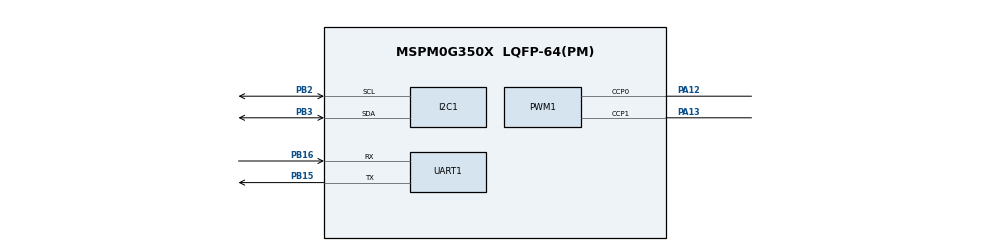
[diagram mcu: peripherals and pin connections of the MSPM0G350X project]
/**
 * @cliArgs --device "MSPM0G350X" --part "Default" --package "LQFP-64(PM)" --product "mspm0_sdk@2.10.00.04"
 * @versions {"tool":"1.27.0+4565"}
 */

/**
 * Import the modules used in this configuration.
 */
const GPIO   = scripting.addModule("/ti/driverlib/GPIO", {}, false);
const GPIO1  = GPIO.addInstance();
const GPIO2  = GPIO.addInstance();
const GPIO3  = GPIO.addInstance();
const GPIO4  = GPIO.addInstance();
const ADC12  = scripting.addModule("/ti/driverlib/ADC12", {}, false);
const ADC121 = ADC12.addInstance();
const I2C    = scripting.addModule("/ti/driverlib/I2C", {}, false);
const I2C1   = I2C.addInstance();
const PWM    = scripting.addModule("/ti/driverlib/PWM", {}, false);
const PWM1   = PWM.addInstance();
const SYSCTL = scripting.addModule("/ti/driverlib/SYSCTL");
const TIMER  = scripting.addModule("/ti/driverlib/TIMER", {}, false);
const TIMER1 = TIMER.addInstance();
const UART   = scripting.addModule("/ti/driverlib/UART", {}, false);
const UART1  = UART.addInstance();
const WWDT   = scripting.addModule("/ti/driverlib/WWDT", {}, false);
const WWDT1  = WWDT.addInstance();

/**
 * Write custom configuration values to the imported modules.
 */
GPIO1.$name                          = "MOTOR";
GPIO1.associatedPins.create(5);
GPIO1.associatedPins[0].assignedPort = "PORTA";
GPIO1.associatedPins[0].$name        = "A_IN1";
GPIO1.associatedPins[0].assignedPin  = "24";
GPIO1.associatedPins[1].assignedPort = "PORTA";
GPIO1.associatedPins[1].$name        = "A_IN2";
GPIO1.associatedPins[1].assignedPin  = "25";
GPIO1.associatedPins[2].assignedPort = "PORTB";
GPIO1.associatedPins[2].assignedPin  = "9";
GPIO1.associatedPins[2].$name        = "B_IN1";
GPIO1.associatedPins[3].assignedPort = "PORTB";
GPIO1.associatedPins[3].assignedPin  = "8";
GPIO1.associatedPins[3].$name        = "B_IN2";
GPIO1.associatedPins[4].assignedPort = "PORTB";
GPIO1.associatedPins[4].assignedPin  = "22";
GPIO1.associatedPins[4].initialValue = "SET";
GPIO1.associatedPins[4].$name        = "STBY";

const Board = scripting.addModule("/ti/driverlib/Board", {}, false);

GPIO2.$name                              = "KEY";
GPIO2.associatedPins.create(3);
GPIO2.associatedPins[0].$name            = "SW1";
GPIO2.associatedPins[0].direction        = "INPUT";
GPIO2.associatedPins[0].internalResistor = "PULL_UP";
GPIO2.associatedPins[0].assignedPort     = "PORTB";
GPIO2.associatedPins[0].assignedPin      = "23";
GPIO2.associatedPins[1].$name            = "SW2";
GPIO2.associatedPins[1].direction        = "INPUT";
GPIO2.associatedPins[1].internalResistor = "PULL_UP";
GPIO2.associatedPins[1].assignedPort     = "PORTA";
GPIO2.associatedPins[1].assignedPin      = "8";
GPIO2.associatedPins[2].$name            = "SW3";
GPIO2.associatedPins[2].direction        = "INPUT";
GPIO2.associatedPins[2].internalResistor = "PULL_UP";
GPIO2.associatedPins[2].assignedPort     = "PORTB";
GPIO2.associatedPins[2].assignedPin      = "6";

GPIO3.$name                              = "ENCODER";
GPIO3.associatedPins.create(4);
GPIO3.associatedPins[0].$name            = "ENC_LA";
GPIO3.associatedPins[0].direction        = "INPUT";
GPIO3.associatedPins[0].assignedPort     = "PORTA";
GPIO3.associatedPins[0].assignedPin      = "14";
GPIO3.associatedPins[0].internalResistor = "PULL_UP";
GPIO3.associatedPins[1].direction        = "INPUT";
GPIO3.associatedPins[1].$name            = "ENC_LB";
GPIO3.associatedPins[1].assignedPort     = "PORTA";
GPIO3.associatedPins[1].assignedPin      = "15";
GPIO3.associatedPins[1].internalResistor = "PULL_UP";
GPIO3.associatedPins[2].direction        = "INPUT";
GPIO3.associatedPins[2].$name            = "ENC_RA";
GPIO3.associatedPins[2].assignedPort     = "PORTB";
GPIO3.associatedPins[2].assignedPin      = "12";
GPIO3.associatedPins[2].internalResistor = "PULL_UP";
GPIO3.associatedPins[3].direction        = "INPUT";
GPIO3.associatedPins[3].$name            = "ENC_RB";
GPIO3.associatedPins[3].assignedPort     = "PORTB";
GPIO3.associatedPins[3].assignedPin      = "13";
GPIO3.associatedPins[3].internalResistor = "PULL_UP";

GPIO4.$name                          = "BOARD_OUTPUT";
GPIO4.associatedPins.create(2);
GPIO4.associatedPins[0].$name        = "LED1";
GPIO4.associatedPins[0].assignedPort = "PORTB";
GPIO4.associatedPins[0].assignedPin  = "4";
GPIO4.associatedPins[0].initialValue = "SET";
GPIO4.associatedPins[1].$name        = "LED2";
GPIO4.associatedPins[1].assignedPort = "PORTB";
GPIO4.associatedPins[1].assignedPin  = "5";
GPIO4.associatedPins[1].initialValue = "SET";

ADC121.$name                      = "POWER_ADC";
ADC121.sampClkDiv                 = "DL_ADC12_CLOCK_DIVIDE_8";
ADC121.adcMem0chansel             = "DL_ADC12_INPUT_CHAN_6";
ADC121.sampleTime0                = "25 us";
ADC121.enabledInterrupts          = ["DL_ADC12_INTERRUPT_MEM0_RESULT_LOADED"];
ADC121.powerDownMode              = "DL_ADC12_POWER_DOWN_MODE_MANUAL";
ADC121.peripheral.$assign         = "ADC1";
ADC121.peripheral.adcPin6.$assign = "PB19";
ADC121.adcPin6Config.$name        = "POWER_ADC_PIN";

I2C1.basicEnableController             = true;
I2C1.$name                             = "I2C_BUS";
I2C1.peripheral.sdaPin.$assign         = "PB3";
I2C1.peripheral.sclPin.$assign         = "PB2";
I2C1.sdaPinConfig.hideOutputInversion  = scripting.forceWrite(false);
I2C1.sdaPinConfig.onlyInternalResistor = scripting.forceWrite(false);
I2C1.sdaPinConfig.passedPeripheralType = scripting.forceWrite("Digital");
I2C1.sdaPinConfig.$name                = "ti_driverlib_gpio_GPIOPinGeneric2";
I2C1.sdaPinConfig.internalResistor     = "PULL_UP";
I2C1.sdaPinConfig.enableConfig         = true;
I2C1.sclPinConfig.hideOutputInversion  = scripting.forceWrite(false);
I2C1.sclPinConfig.onlyInternalResistor = scripting.forceWrite(false);
I2C1.sclPinConfig.passedPeripheralType = scripting.forceWrite("Digital");
I2C1.sclPinConfig.$name                = "ti_driverlib_gpio_GPIOPinGeneric3";
I2C1.sclPinConfig.enableConfig         = true;
I2C1.sclPinConfig.internalResistor     = "PULL_UP";

PWM1.$name                      = "PWM_0";
PWM1.pwmMode                    = "EDGE_ALIGN_UP";
PWM1.timerStartTimer            = true;
PWM1.peripheral.ccp0Pin.$assign = "PA12";
PWM1.peripheral.ccp1Pin.$assign = "PA13";
PWM1.PWM_CHANNEL_0.$name        = "ti_driverlib_pwm_PWMTimerCC0";
PWM1.PWM_CHANNEL_1.$name        = "ti_driverlib_pwm_PWMTimerCC1";
PWM1.ccp0PinConfig.$name        = "ti_driverlib_gpio_GPIOPinGeneric0";
PWM1.ccp1PinConfig.$name        = "ti_driverlib_gpio_GPIOPinGeneric1";

TIMER1.$name              = "CTRL_TIMER";
TIMER1.timerPeriod        = "1 ms";
TIMER1.timerMode          = "PERIODIC";
TIMER1.interrupts         = ["ZERO"];
TIMER1.peripheral.$assign = "TIMG12";

UART1.$name                    = "UART_0";
UART1.targetBaudRate           = 115200;
UART1.enableFIFO               = false;
UART1.enabledInterrupts        = ["RX"];
UART1.peripheral.$assign       = "UART2";
UART1.peripheral.txPin.$assign = "PB15";
UART1.peripheral.rxPin.$assign = "PB16";

WWDT1.$name               = "WWDT0";
WWDT1.clockDivider        = "8";
WWDT1.periodCount         = "12";
WWDT1.activeWindow        = "0";
WWDT1.window0ClosedPeriod = "0";
WWDT1.window1ClosedPeriod = "0";
WWDT1.sleepMode           = true;

SYSCTL.forceDefaultClkConfig = true;

/**
 * Pinmux solution for unlocked pins/peripherals. This ensures that minor changes to the automatic solver in a future
 * version of the tool will not impact the pinmux you originally saw.  These lines can be completely deleted in order to
 * re-solve from scratch.
 */
GPIO1.associatedPins[0].pin.$suggestSolution = "PA24";
GPIO1.associatedPins[1].pin.$suggestSolution = "PA25";
GPIO1.associatedPins[2].pin.$suggestSolution = "PB9";
GPIO1.associatedPins[3].pin.$suggestSolution = "PB8";
GPIO1.associatedPins[4].pin.$suggestSolution = "PB22";
Board.peripheral.$suggestSolution            = "DEBUGSS";
Board.peripheral.swclkPin.$suggestSolution   = "PA20";
Board.peripheral.swdioPin.$suggestSolution   = "PA19";
GPIO2.associatedPins[0].pin.$suggestSolution = "PB23";
GPIO2.associatedPins[1].pin.$suggestSolution = "PA8";
GPIO2.associatedPins[2].pin.$suggestSolution = "PB6";
GPIO3.associatedPins[0].pin.$suggestSolution = "PA14";
GPIO3.associatedPins[1].pin.$suggestSolution = "PA15";
GPIO3.associatedPins[2].pin.$suggestSolution = "PB12";
GPIO3.associatedPins[3].pin.$suggestSolution = "PB13";
GPIO4.associatedPins[0].pin.$suggestSolution = "PB4";
GPIO4.associatedPins[1].pin.$suggestSolution = "PB5";
ADC121.peripheral.$suggestSolution           = "ADC1";
I2C1.peripheral.$suggestSolution             = "I2C1";
PWM1.peripheral.$suggestSolution             = "TIMG0";
UART1.peripheral.$suggestSolution            = "UART2";
UART1.peripheral.txPin.$suggestSolution      = "PB15";
UART1.peripheral.rxPin.$suggestSolution      = "PB16";
WWDT1.peripheral.$suggestSolution            = "WWDT0";
SYSCTL.peripheral.$suggestSolution           = "SYSCTL";
